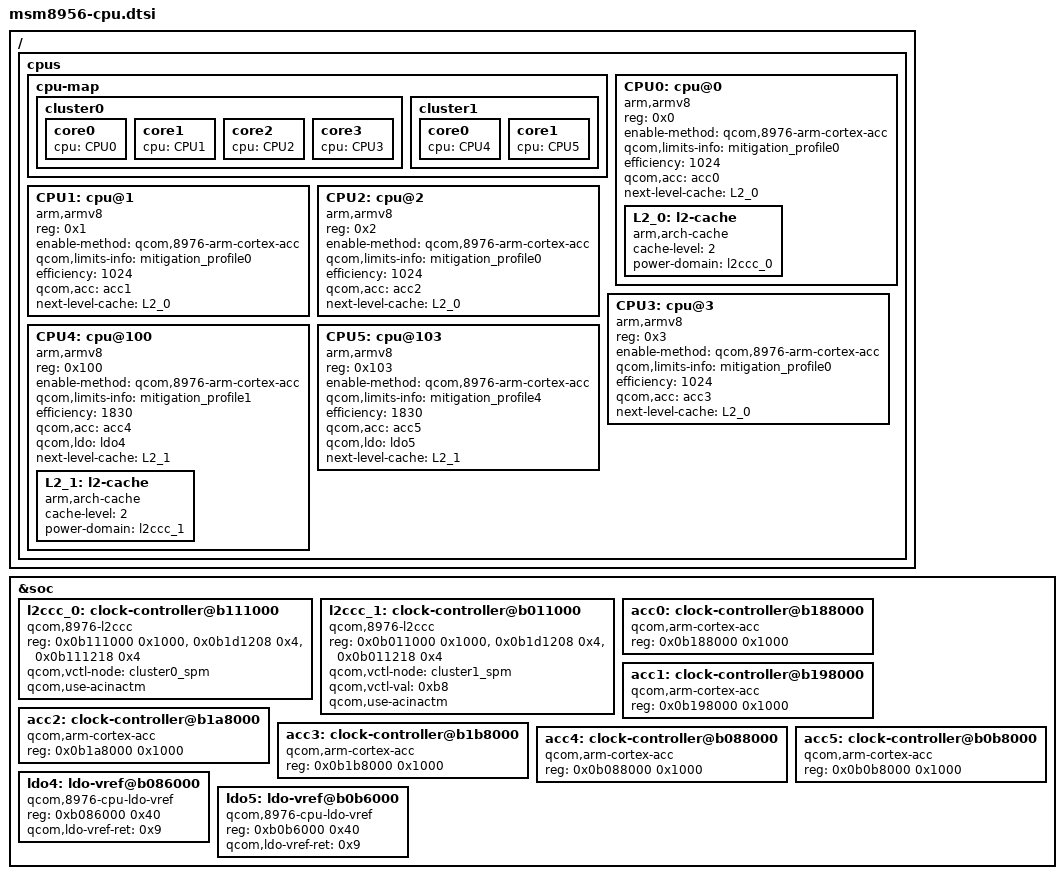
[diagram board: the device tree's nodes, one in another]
/* Copyright (c) 2015, The Linux Foundation. All rights reserved.
 *
 * This program is free software; you can redistribute it and/or modify
 * it under the terms of the GNU General Public License version 2 and
 * only version 2 as published by the Free Software Foundation.
 *
 * This program is distributed in the hope that it will be useful,
 * but WITHOUT ANY WARRANTY; without even the implied warranty of
 * MERCHANTABILITY or FITNESS FOR A PARTICULAR PURPOSE.  See the
 * GNU General Public License for more details.
 */


/ {
	cpus {
		#address-cells = <1>;
		#size-cells = <0>;
		cpu-map {
			cluster0 {
				core0 {
					cpu = <&CPU0>;
				};
				core1 {
					cpu = <&CPU1>;
				};
				core2 {
					cpu = <&CPU2>;
				};
				core3 {
					cpu = <&CPU3>;
				};
			};

			cluster1 {
				core0 {
					cpu = <&CPU4>;
				};
				core1 {
					cpu = <&CPU5>;
				};
			};
		};

		CPU0: cpu@0 {
			device_type = "cpu";
			compatible = "arm,armv8";
			reg = <0x0>;
			enable-method = "qcom,8976-arm-cortex-acc";
			qcom,limits-info = <&mitigation_profile0>;
			efficiency = <1024>;
			qcom,acc = <&acc0>;
			next-level-cache = <&L2_0>;
			L2_0: l2-cache {
			      compatible = "arm,arch-cache";
			      cache-level = <2>;
			      power-domain = <&l2ccc_0>;
			};
		};

		CPU1: cpu@1 {
			device_type = "cpu";
			compatible = "arm,armv8";
			reg = <0x1>;
			enable-method = "qcom,8976-arm-cortex-acc";
			qcom,limits-info = <&mitigation_profile0>;
			efficiency = <1024>;
			qcom,acc = <&acc1>;
			next-level-cache = <&L2_0>;
		};

		CPU2: cpu@2 {
			device_type = "cpu";
			compatible = "arm,armv8";
			reg = <0x2>;
			enable-method = "qcom,8976-arm-cortex-acc";
			qcom,limits-info = <&mitigation_profile0>;
			efficiency = <1024>;
			qcom,acc = <&acc2>;
			next-level-cache = <&L2_0>;
		};

		CPU3: cpu@3 {
			device_type = "cpu";
			compatible = "arm,armv8";
			reg = <0x3>;
			enable-method = "qcom,8976-arm-cortex-acc";
			qcom,limits-info = <&mitigation_profile0>;
			efficiency = <1024>;
			qcom,acc = <&acc3>;
			next-level-cache = <&L2_0>;
		};

		CPU4: cpu@100 {
			device_type = "cpu";
			compatible = "arm,armv8";
			reg = <0x100>;
			enable-method = "qcom,8976-arm-cortex-acc";
			qcom,limits-info = <&mitigation_profile1>;
			efficiency = <1830>;
			qcom,acc = <&acc4>;
			qcom,ldo = <&ldo4>;
			next-level-cache = <&L2_1>;
			L2_1: l2-cache {
			      compatible = "arm,arch-cache";
			      cache-level = <2>;
			      power-domain = <&l2ccc_1>;
			      };
			};

		CPU5: cpu@103 {
			device_type = "cpu";
			compatible = "arm,armv8";
			reg = <0x103>;
			enable-method = "qcom,8976-arm-cortex-acc";
			qcom,limits-info = <&mitigation_profile4>;
			efficiency = <1830>;
			qcom,acc = <&acc5>;
			qcom,ldo = <&ldo5>;
			next-level-cache = <&L2_1>;
		};
	};
};

&soc {

	l2ccc_0: clock-controller@b111000 {
		compatible = "qcom,8976-l2ccc";
		reg = <0x0b111000 0x1000>,
		      <0x0b1d1208 0x4>,
		      <0x0b111218 0x4>;
		reg-names = "l2-base", "l2-common",
				"l2-acinactm";
		qcom,vctl-node = <&cluster0_spm>;
		qcom,use-acinactm;
	};

	l2ccc_1: clock-controller@b011000 {
		compatible = "qcom,8976-l2ccc";
		reg = <0x0b011000 0x1000>,
		      <0x0b1d1208 0x4>,
		      <0x0b011218 0x4>;
		reg-names = "l2-base", "l2-common",
				"l2-acinactm";
		qcom,vctl-node = <&cluster1_spm>;
		qcom,vctl-val = <0xb8>;
		qcom,use-acinactm;
	};

	acc0:clock-controller@b188000 {
		compatible = "qcom,arm-cortex-acc";
		reg = <0x0b188000 0x1000>;
	};

	acc1:clock-controller@b198000 {
		compatible = "qcom,arm-cortex-acc";
		reg = <0x0b198000 0x1000>;
	};

	acc2:clock-controller@b1a8000 {
		compatible = "qcom,arm-cortex-acc";
		reg = <0x0b1a8000 0x1000>;
	};

	acc3:clock-controller@b1b8000 {
		compatible = "qcom,arm-cortex-acc";
		reg = <0x0b1b8000 0x1000>;
	};

	acc4:clock-controller@b088000 {
		compatible = "qcom,arm-cortex-acc";
		reg = <0x0b088000 0x1000>;
	};

	acc5:clock-controller@b0b8000 {
		compatible = "qcom,arm-cortex-acc";
		reg = <0x0b0b8000 0x1000>;
	};

	ldo4:ldo-vref@b086000 {
		compatible = "qcom,8976-cpu-ldo-vref";
		reg = <0xb086000 0x40>;
		qcom,ldo-vref-ret = <0x9>;
	};

	ldo5:ldo-vref@b0b6000 {
		compatible = "qcom,8976-cpu-ldo-vref";
		reg = <0xb0b6000 0x40>;
		qcom,ldo-vref-ret = <0x9>;
	};
};
